# CY8C5868AXI_LP035 register map
File version: 0.1
CY8C58LP
Registers are 8-bit, read-write, no defined reset value unless marked. A register's access mark holds for its fields unless they carry their own. Offsets are from the block's base; lines under a group give offsets from that group; [hi:lo] are bit positions; {n}, {i} and the like mark numbered series; 'fields as' and 'values as' point back to an identical list; <NAME> marks a mode.

## Memory map
0x40004394 USBFS size 0x1D0A
0x400043A4 Opamp_1 size 0x17A2
0x400043A6 Filter size 0x840F
0x400043A8 WaveDAC8_VDAC8 size 0x17D9
0x400043AA ADC_DelSig size 0x17E0

## Opamp_1
Base 0x400043A4
0x00 PM_ACT_CFG4 — Active Power Mode Configuration Register 4
  [3:0] EN_OPAMP — Enables subsystems during active power mode
    0=Blk_0 (Enables analog linear output buffer for Opamp block 0); 2=Blk_1 (Enables analog linear output buffer for Opamp block 1); 4=Blk_2 (Enables analog linear output buffer for Opamp block 2); 8=Blk_3 (Enables analog linear output buffer for Opamp block 3)
0x10 PM_STBY_CFG4 — Standby Power Mode Configuration Register 4
  [3:0] EN_OPAMP — Enables subsystems during standby power mode
    values as PM_ACT_CFG4.EN_OPAMP
0x280 OPAMP__TR0 — Analog Output Buffer Trim Register 0
  [4:0] offset_trim — Offset Trim: 420uV typical step size; +/- 6.8mV offset trimmable range
0x281 OPAMP__TR1 — Analog Output Buffer Trim Register 1
0x14B8 OPAMP__CR — Analog Output Buffer Configuration Register
  [1:0] pwr_mode — Power Mode
    0=Default_Fast (Default Power mode Fast); 1=Slow (Power Mode Slow); 2=Medium (Power Mode Medium); 3=Fast (Power Mode Fast)
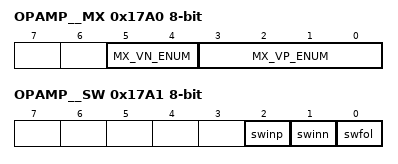
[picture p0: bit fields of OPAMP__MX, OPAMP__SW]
0x17A0 OPAMP__MX — Analog Buffer Input Selection Register
  [5:4] MX_VN_ENUM — MUX select VN (Negative terminal input)
    0=OPAMP0_MX_VN_DEFAULT (Default - Not Connected (NC)); 1=OPAMP0_MX_VN_AG4 (MUX Selection AGL(4)); 2=OPAMP0_MX_VN_AG6 (MUX Selection AGL(6)); 3=OPAMP0_MX_VN_0x3 (Reserved (NC))
  [3:0] MX_VP_ENUM — MUX select VP (Positive terminal input)
    0=OPAMP0_MX_VP_DEFAULT (Default - Not Connected (NC)); {v}=OPAMP0_MX_VP_AG{v+3} (MUX Selection AGL({v+3})) (v=1..4); {v}=OPAMP0_MX_VP_ABUS{v-5} (MUX Selection ABUSL({v-5})) (v=5..8); 9=OPAMP0_MX_VP_VREF (MUX Selection: OPAMP Voltage Reference); {v}=OPAMP0_MX_VP_H_{0x0+v} (Reserved (NC)) (v=10..15)
0x17A1 OPAMP__SW — Analog Buffer Routing Switch Register
  [2] swinp — Switch Enable Positive Input
  [1] swinn — Switch Enable Negative Input
  [0] swfol — Switch Enable Follow

## USBFS
Base 0x40004394
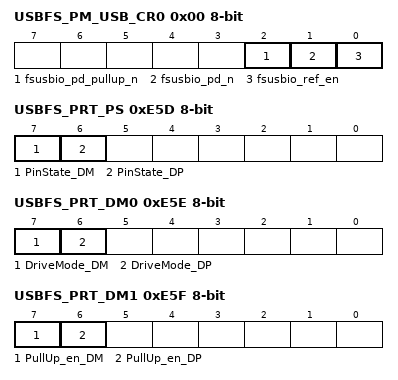
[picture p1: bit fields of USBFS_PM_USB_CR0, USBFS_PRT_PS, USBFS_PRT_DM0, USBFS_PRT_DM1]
0x00 USBFS_PM_USB_CR0 — USB Power Mode Control Register 0
  [2] fsusbio_pd_pullup_n, [1] fsusbio_pd_n, [0] fsusbio_ref_en
0x11 USBFS_PM_ACT_CFG — Active Power Mode Configuration Register
0x21 USBFS_PM_STBY_CFG — Standby Power Mode Configuration Register
0xE5D USBFS_PRT_PS — Port Pin State Register
  [7] PinState_DM ro, [6] PinState_DP ro
0xE5E USBFS_PRT_DM0 — Port Drive Mode Register
  [7] DriveMode_DM, [6] DriveMode_DP
0xE5F USBFS_PRT_DM1 — Port Drive Mode Register
  [7] PullUp_en_DM, [6] PullUp_en_DP
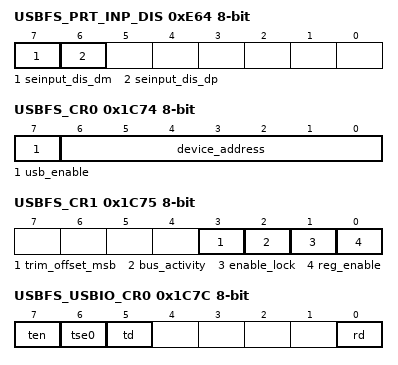
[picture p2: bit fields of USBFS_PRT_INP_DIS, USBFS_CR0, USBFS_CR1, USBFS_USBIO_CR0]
0xE64 USBFS_PRT_INP_DIS — Input buffer disable override
  [7] seinput_dis_dm, [6] seinput_dis_dp
0x1C6C USBFS_EP0_DR0 — bmRequestType
0x1C6D USBFS_EP0_DR1 — bRequest
0x1C6E USBFS_EP0_DR2 — wValueLo
0x1C6F USBFS_EP0_DR3 — wValueHi
0x1C70 USBFS_EP0_DR4 — wIndexLo
0x1C71 USBFS_EP0_DR5 — wIndexHi
0x1C72 USBFS_EP0_DR6 — lengthLo
0x1C73 USBFS_EP0_DR7 — lengthHi
0x1C74 USBFS_CR0 — USB Control Register 0
  [7] usb_enable, [6:0] device_address ro
0x1C75 USBFS_CR1 — USB Control Register 1
  [3] trim_offset_msb, [2] bus_activity, [1] enable_lock, [0] reg_enable
{0x1C6A+0x10*i} USBFS_SIE_EP{i}_CR0 (i=1..8) — The Endpoint{i} Control Register
0x1C7C USBFS_USBIO_CR0 — USBIO Control Register 0
  [7] ten, [6] tse0, [5] td, [0] rd ro
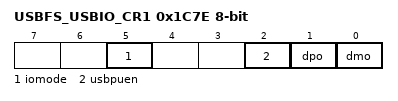
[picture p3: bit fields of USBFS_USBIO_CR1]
0x1C7E USBFS_USBIO_CR1 — USBIO Control Register 1
  [5] iomode, [2] usbpuen, [1] dpo ro, [0] dmo ro
0x1CF8 USBFS_BUF_SIZE — Dedicated Endpoint Buffer Size Register
0x1CFA USBFS_EP_ACTIVE — Endpoint Active Indication Register
0x1CFB USBFS_EP_TYPE — Endpoint Type (IN/OUT) Indication
0x1D09 USBFS_USB_CLK_EN — USB Block Clock Enable Register
